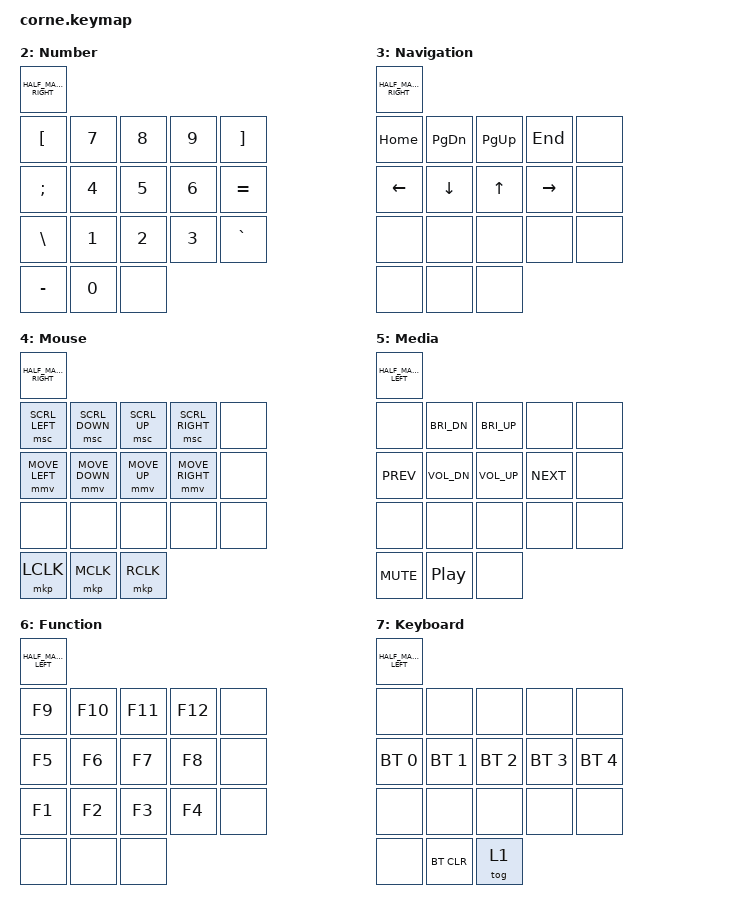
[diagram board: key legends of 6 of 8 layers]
/*
 * Copyright (c) 2020 The ZMK Contributors
 *
 * SPDX-License-Identifier: MIT
 */

#include <behaviors.dtsi>
#include <dt-bindings/zmk/keys.h>
#include <dt-bindings/zmk/bt.h>
#include <dt-bindings/zmk/pointing.h>



#define PLAIN_ROW(AL, BL, CL, DL, EL, AR, BR, CR, DR, ER) \
    &kp AL &kp BL &kp CL &kp DL &kp EL\
    &kp AR &kp BR &kp CR &kp DR &kp ER

#define HMODS_ROW(AL, BL, CL, DL, EL, AR, BR, CR, DR, ER) \
    &hml LCTRL AL &hml LALT BL &hml LGUI CL &hml LSHFT DL &kp EL\
    &kp AR &hmr LSHFT BR &hmr LGUI CR &hmr LALT DR &hmr LCTRL ER

#define BASE_THUMB_L &slt 4 CAPS &rlt 3 BSPC &rlt 2 SPACE

#define BASE_THUMB_R &rlt 5 RET &rlt 6 TAB &slt 7 ESC

#define BASE_MATRIX(TL1, TL2, TL3, TL4, TL5,  TR1, TR2, TR3, TR4, TR5,\
                    ML1, ML2, ML3, ML4, ML5,  MR1, MR2, MR3, MR4, MR5,\
                    BL1, BL2, BL3, BL4, BL5,  BR1, BR2, BR3, BR4, BR5) \
    PLAIN_ROW(TL1, TL2, TL3, TL4, TL5, TR1, TR2, TR3, TR4, TR5)\
    HMODS_ROW(ML1, ML2, ML3, ML4, ML5, MR1, MR2, MR3, MR4, MR5)\
    PLAIN_ROW(BL1, BL2, BL3, BL4, BL5, BR1, BR2, BR3, BR4, BR5)\
    BASE_THUMB_L BASE_THUMB_R



#define BLANK_HALF_ROW  &none &none &none &none  &none

#define PLAIN_HALF_ROW(A, B, C, D, E) \
    &kp A &kp B &kp C &kp D &kp E

#define MOD_HALF_ROW_L &kp LCTRL &kp LALT &kp LGUI &kp LSHFT &none

#define MOD_HALF_ROW_R &none &kp LSHFT &kp LGUI &kp LALT &kp LCTRL

#define BLANK_THUMB &none &none &none

#define HALF_MATRIX_LEFT(TL1, TL2, TL3, TL4, TL5,\
                         ML1, ML2, ML3, ML4, ML5,\
                         BL1, BL2, BL3, BL4, BL5,\
                         T1, T2, T3) \
    TL1 TL2 TL3 TL4 TL5    BLANK_HALF_ROW\
    ML1 ML2 ML3 ML4 ML5    MOD_HALF_ROW_R\
    BL1 BL2 BL3 BL4 BL5    BLANK_HALF_ROW\
               T1 T2 T3    BLANK_THUMB

#define HALF_MATRIX_RIGHT(TR1, TR2, TR3, TR4, TR5,\
                          MR1, MR2, MR3, MR4, MR5,\
                          BR1, BR2, BR3, BR4, BR5,\
                          T1, T2, T3) \
    BLANK_HALF_ROW    TR1 TR2 TR3 TR4 TR5\
    MOD_HALF_ROW_R    MR1 MR2 MR3 MR4 MR5\
    BLANK_HALF_ROW    BR1 BR2 BR3 BR4 BR5\
       BLANK_THUMB    T1 T2 T3



/* Constants */
#define QUICK_TAP_TERM 175
#define PRIOR_IDLE 150
#define TAPPING_TERM 250


/ {
    chosen {
        zmk,physical-layout = &foostan_corne_5col_layout;
    };

    behaviors {
        hml: home_row_mod_left {
            compatible = "zmk,behavior-hold-tap";
            #binding-cells = <2>;
            flavor = "balanced";
            require-prior-idle-ms = <PRIOR_IDLE>;
            tapping-term-ms = <TAPPING_TERM>;
            quick-tap-ms = <QUICK_TAP_TERM>;
            bindings = <&kp>, <&kp>;
            hold-trigger-key-positions = <
                5  6  7  8  9
                15 16 17 18 19
                25 26 27 28 29
                33 34 35
            >; // List of keys on the right side of the keyboard
            hold-trigger-on-release;
        };

        hmr: home_row_mod_right {
            compatible = "zmk,behavior-hold-tap";
            #binding-cells = <2>;
            flavor = "balanced";
            require-prior-idle-ms = <PRIOR_IDLE>;
            tapping-term-ms = <TAPPING_TERM>;
            quick-tap-ms = <QUICK_TAP_TERM>;
            bindings = <&kp>, <&kp>;
            hold-trigger-key-positions = <
                0  1  2  3  4
                10 11 12 13 14
                20 21 22 23 24
                      30 31 32
            >; // List of keys on the left side of the keyboard
            hold-trigger-on-release;
        };

        slt: simple_layer_tap {
            compatible = "zmk,behavior-hold-tap";
            #binding-cells = <2>;
            flavor = "tap-preferred";
            tapping-term-ms = <TAPPING_TERM>;
            bindings = <&mo>, <&kp>;
        };

        rlt: repeating_layer_tap {
            compatible = "zmk,behavior-hold-tap";
            #binding-cells = <2>;
            flavor = "tap-preferred";
            tapping-term-ms = <TAPPING_TERM>;
            bindings = <&mo>, <&kp>;
            quick-tap-ms = <QUICK_TAP_TERM>;
        };

        keymap {
            compatible = "zmk,keymap";

            defaut_layer {
                display-name = "QWERTY";
                bindings = <
                    BASE_MATRIX(
                        Q, W, E, R, T,    Y, U, I,     O,   P,
                        A, S, D, F, G,    H, J, K,     L,   SQT,
                        Z, X, C, V, B,    N, M, COMMA, DOT, FSLH
                    )
                >;
            };

            graphite_layer {
                display-name = "Graphite";
                bindings = <
                    BASE_MATRIX(
                        B, L, D, W, Z,    SQT, F, O,     U,   J,
                        N, R, T, S, G,    Y,   H, A,     E,   I,
                        Q, X, M, C, V,    K,   P, COMMA, DOT, FSLH
                    )
                >;
            };

            number_layer {
                display-name = "Number";
                bindings = <
                    HALF_MATRIX_RIGHT(
                        &kp LBKT, &kp N7, &kp N8, &kp N9, &kp RBKT,
                        &kp SEMI, &kp N4, &kp N5, &kp N6, &kp EQUAL,
                        &kp BSLH, &kp N1, &kp N2, &kp N3, &kp GRAVE,
                        &kp MINUS, &kp N0, &none
                    )
                >;
            };

            navigation_layer {
                display-name = "Navigation";
                bindings = <
                    HALF_MATRIX_RIGHT(
                        &kp HOME, &kp PG_DN, &kp PG_UP, &kp END,   &none,
                        &kp LEFT, &kp DOWN,  &kp UP,    &kp RIGHT, &none,
                        &none,    &none,     &none,     &none,     &none,
                        &none, &none, &none
                    )
                >;
            };

            mouse_layer {
                display-name = "Mouse";
                bindings = <
                    HALF_MATRIX_RIGHT(
                        &msc SCRL_LEFT, &msc SCRL_DOWN, &msc SCRL_UP, &msc SCRL_RIGHT, &none,
                        &mmv MOVE_LEFT, &mmv MOVE_DOWN, &mmv MOVE_UP, &mmv MOVE_RIGHT, &none,
                        &none,          &none,          &none,        &none,           &none,
                        &mkp LCLK, &mkp MCLK, &mkp RCLK
                    )
                >;
            };

            media_layer {
                display-name = "Media";
                bindings = <
                    HALF_MATRIX_LEFT(
                        &none,      &kp C_BRI_DN, &kp C_BRI_UP, &none,      &none,
                        &kp C_PREV, &kp C_VOL_DN, &kp C_VOL_UP, &kp C_NEXT, &none,
                        &none,      &none,        &none,        &none,      &none,
                                                      &kp C_MUTE, &kp C_PP, &none
                    )
                >;
            };

            function_layer {
                display-name = "Function";
                bindings = <
                    HALF_MATRIX_LEFT(
                        &kp F9, &kp F10, &kp F11, &kp F12, &none,
                        &kp F5, &kp F6,  &kp F7,  &kp F8,  &none,
                        &kp F1, &kp F2,  &kp F3,  &kp F4,  &none,
                                             &none, &none, &none
                    )
                >;
            };

            keyboard_layer {
                display-name = "Keyboard";
                bindings = <
                    HALF_MATRIX_LEFT(
                        &none,        &none,        &none,        &none,        &none,
                        &bt BT_SEL 0, &bt BT_SEL 1, &bt BT_SEL 2, &bt BT_SEL 3, &bt BT_SEL 4,
                        &none,        &none,        &none,        &none,        &none,
                                                                   &none, &bt BT_CLR, &tog 1
                    )
                >;
            };
        };
    };
};
